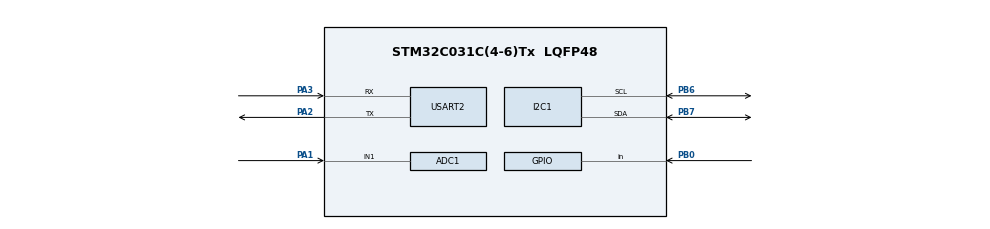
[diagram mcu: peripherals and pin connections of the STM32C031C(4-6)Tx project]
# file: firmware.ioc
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ADC1.NbrOfConversionFlag=0
ADC1.SelectedChannel=ADC_CHANNEL_1
ADC1.master=1
I2C1.Timing=0x10805D88
Mcu.Family=STM32C0
Mcu.Name=STM32C031C(4-6)Tx
Mcu.Package=LQFP48
NUCLEO-C031C6.BUTTON=1
NUCLEO-C031C6.LD4=true
NUCLEO-C031C6.VCP=false
NVIC.EXTI4_15_IRQn=true\:0\:0\:false\:false\:true\:false\:true\:true
PA1.Mode=IN1
PA1.Signal=ADC1_IN1
PA13.GPIO_Label=DEBUG_SWDIO
PA13.Signal=DEBUG_SWDIO
PA14-BOOT0.GPIO_Label=DEBUG_SWCLK
PA14-BOOT0.Signal=DEBUG_SWCLK
PA2.Mode=Asynchronous
PA2.Signal=USART2_TX
PA3.Mode=Asynchronous
PA3.Signal=USART2_RX
PB0.GPIO_PuPd=GPIO_PULLUP
PB0.Signal=GPIO_Input
PB6.Mode=I2C
PB6.Signal=I2C1_SCL
PB7.Mode=I2C
PB7.Signal=I2C1_SDA
PC14-OSCX_IN\ (PC14).GPIO_Label=RCC_OSCX_IN
PC14-OSCX_IN\ (PC14).Mode=LSE-External-Oscillator
PC14-OSCX_IN\ (PC14).Signal=RCC_OSCX_IN
PC15-OSCX_OUT\ (PC15).GPIO_Label=RCC_OSCX_OUT
PC15-OSCX_OUT\ (PC15).Mode=LSE-External-Oscillator
PC15-OSCX_OUT\ (PC15).Signal=RCC_OSCX_OUT
PF0-OSC_IN\ (PF0).GPIO_Label=RCC_OSC_IN
PF0-OSC_IN\ (PF0).Signal=RCC_OSC_IN
PF1-OSC_OUT\ (PF1).GPIO_Label=RCC_OSC_OUT
PF1-OSC_OUT\ (PF1).Signal=RCC_OSC_OUT
ProjectManager.HeapSize=0x200
ProjectManager.StackSize=0x400
ProjectManager.TargetToolchain=Makefile
RCC.ADCFreq_Value=48000000
RCC.AHBFreq_Value=48000000
RCC.CortexFreq_Value=48000000
RCC.EXTERNAL_CLOCK_VALUE=12288000
RCC.HCLKFreq_Value=48000000
RCC.HSE_VALUE=48000000
RCC.HSISYSCLKDivider=RCC_HSI_DIV1
RCC.HSI_VALUE=48000000
RCC.SYSCLKFreq_VALUE=48000000
USART2.VirtualMode-Asynchronous=VM_ASYNC
VP_NUCLEO-C031C6_VS_BSP_COMMON.Mode=COMMON
board=NUCLEO-C031C6

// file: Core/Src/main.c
/* USER CODE BEGIN Header */
/**
  ******************************************************************************
  * @file           : main.c
  * @brief          : Main program body
  ******************************************************************************
  * @attention
  *
  * Copyright (c) 2026 STMicroelectronics.
  * All rights reserved.
  *
  * This software is licensed under terms that can be found in the LICENSE file
  * in the root directory of this software component.
  * If no LICENSE file comes with this software, it is provided AS-IS.
  *
  ******************************************************************************
  */
/* USER CODE END Header */
#include "main.h"
#include "adc.h"
#include "i2c.h"
#include "usart.h"
#include "gpio.h"

/* USER CODE BEGIN Includes */

#include "app.h"

/* USER CODE END Includes */

void SystemClock_Config(void);

int main(void)
{

  /* MCU Configuration--------------------------------------------------------*/

  /* Reset of all peripherals, Initializes the Flash interface and the Systick. */
  HAL_Init();

  /* Configure the system clock */
  SystemClock_Config();

  /* Initialize all configured peripherals */
  MX_GPIO_Init();
  MX_ADC1_Init();
  MX_I2C1_Init();
  MX_USART2_UART_Init();
  /* USER CODE BEGIN 2 */

  /*
   * Initialize our laboratory application:
   * UART logging
   * BMP180 check
   * ADC / GPIO preparation
   */
  App_Init();

  /* USER CODE END 2 */

  /* Infinite loop */
  /* USER CODE BEGIN WHILE */

  while (1)
  {
    /*
     * Main laboratory application.
     *
     * Reads:
     * - ADC potentiometer
     * - PB0 button
     * - BMP180 state
     *
     * and outputs telemetry via UART.
     */
    App_Loop();

    /* USER CODE END WHILE */

  }
}

void SystemClock_Config(void)
{
  RCC_OscInitTypeDef RCC_OscInitStruct = {0};
  RCC_ClkInitTypeDef RCC_ClkInitStruct = {0};

  __HAL_FLASH_SET_LATENCY(FLASH_LATENCY_1);

  /** Initializes the RCC Oscillators according to the specified parameters
  * in the RCC_OscInitTypeDef structure.
  */
  RCC_OscInitStruct.OscillatorType = RCC_OSCILLATORTYPE_HSI;
  RCC_OscInitStruct.HSIState = RCC_HSI_ON;
  RCC_OscInitStruct.HSIDiv = RCC_HSI_DIV1;
  RCC_OscInitStruct.HSICalibrationValue = RCC_HSICALIBRATION_DEFAULT;
  if (HAL_RCC_OscConfig(&RCC_OscInitStruct) != HAL_OK)
  {
    Error_Handler();
  }

  /** Initializes the CPU, AHB and APB buses clocks
  */
  RCC_ClkInitStruct.ClockType = RCC_CLOCKTYPE_HCLK|RCC_CLOCKTYPE_SYSCLK
                              |RCC_CLOCKTYPE_PCLK1;
  RCC_ClkInitStruct.SYSCLKSource = RCC_SYSCLKSOURCE_HSI;
  RCC_ClkInitStruct.SYSCLKDivider = RCC_SYSCLK_DIV1;
  RCC_ClkInitStruct.AHBCLKDivider = RCC_HCLK_DIV1;
  RCC_ClkInitStruct.APB1CLKDivider = RCC_APB1_DIV1;

  if (HAL_RCC_ClockConfig(&RCC_ClkInitStruct, FLASH_LATENCY_1) != HAL_OK)
  {
    Error_Handler();
  }
}

void Error_Handler(void)
{
  __disable_irq();
  while (1)
  {
  }
}
#ifdef USE_FULL_ASSERT
/**
  * @brief  Reports the name of the source file and the source line number
  *         where the assert_param error has occurred.
  * @param  file: pointer to the source file name
  * @param  line: assert_param error line source number
  * @retval None
  */
void assert_failed(uint8_t *file, uint32_t line)
{
  /* USER CODE BEGIN 6 */

  (void)file;
  (void)line;

  /* USER CODE END 6 */
}
#endif /* USE_FULL_ASSERT */
